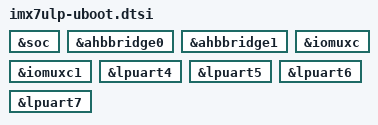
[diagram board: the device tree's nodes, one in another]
/*
 * Copyright 2015-2016 Freescale Semiconductor, Inc.
 *
 * This program is free software; you can redistribute it and/or modify
 * it under the terms of the GNU General Public License version 2 as
 * published by the Free Software Foundation.
 */

&soc {
       u-boot,dm-all;
};

&ahbbridge0 {
       u-boot,dm-all;
};

&ahbbridge1 {
       u-boot,dm-all;
};

&iomuxc {
       u-boot,dm-all;
};

&iomuxc1 {
       u-boot,dm-all;
};

&lpuart4 {
       u-boot,dm-all;
};

&lpuart5 {
       u-boot,dm-all;
};

&lpuart6 {
       u-boot,dm-all;
};

&lpuart7 {
       u-boot,dm-all;
};
